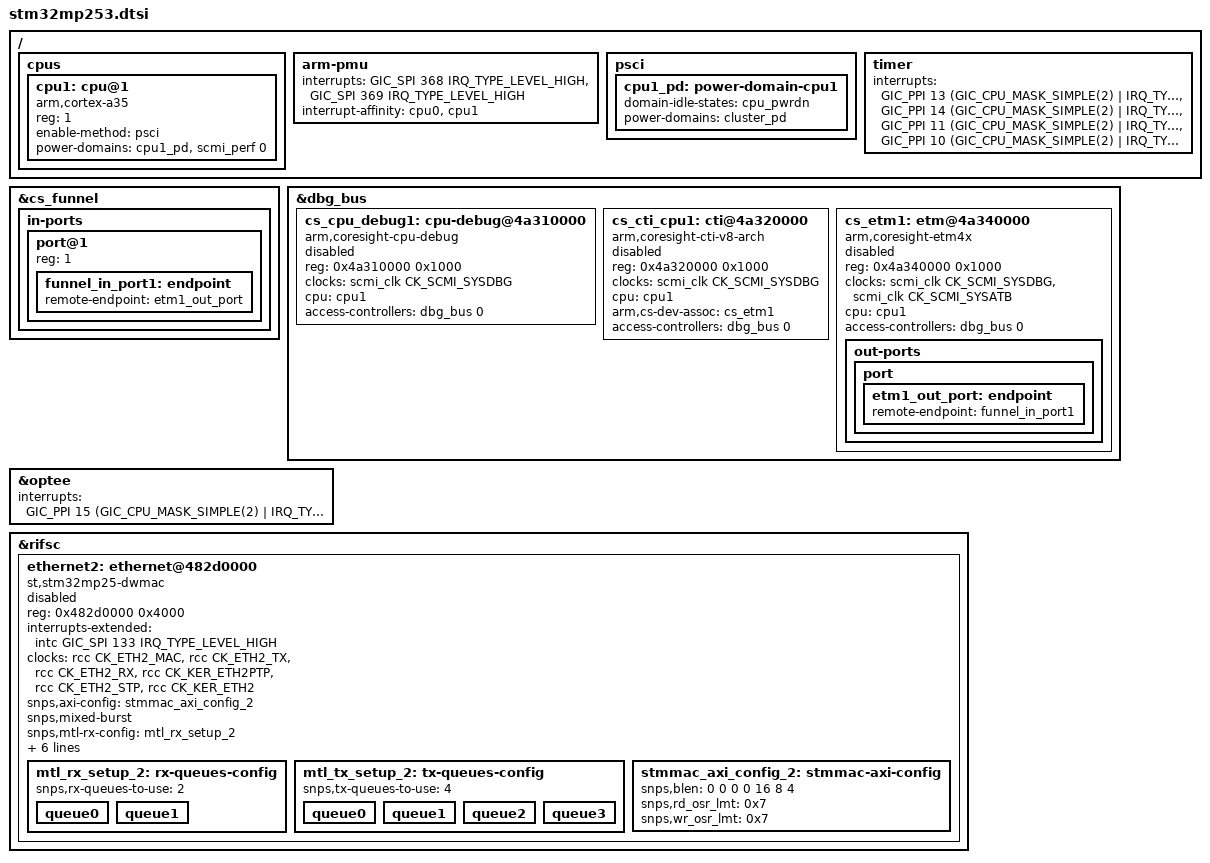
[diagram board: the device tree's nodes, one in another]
// SPDX-License-Identifier: (GPL-2.0-or-later OR BSD-3-Clause)
/*
 * Copyright (C) STMicroelectronics 2023 - All Rights Reserved
 * Author: Alexandre Torgue <alexandre.torgue@foss.st.com> for STMicroelectronics.
 */
#include "stm32mp251.dtsi"

/ {
	cpus {
		cpu1: cpu@1 {
			compatible = "arm,cortex-a35";
			device_type = "cpu";
			reg = <1>;
			enable-method = "psci";
			power-domains = <&cpu1_pd>, <&scmi_perf 0>;
			power-domain-names = "psci", "perf";
		};
	};

	arm-pmu {
		interrupts = <GIC_SPI 368 IRQ_TYPE_LEVEL_HIGH>,
			     <GIC_SPI 369 IRQ_TYPE_LEVEL_HIGH>;
		interrupt-affinity = <&cpu0>, <&cpu1>;
	};

	psci {
		cpu1_pd: power-domain-cpu1 {
			#power-domain-cells = <0>;
			domain-idle-states =  <&cpu_pwrdn>;
			power-domains = <&cluster_pd>;
		};
	};

	timer {
		interrupts = <GIC_PPI 13 (GIC_CPU_MASK_SIMPLE(2) | IRQ_TYPE_LEVEL_LOW)>,
			     <GIC_PPI 14 (GIC_CPU_MASK_SIMPLE(2) | IRQ_TYPE_LEVEL_LOW)>,
			     <GIC_PPI 11 (GIC_CPU_MASK_SIMPLE(2) | IRQ_TYPE_LEVEL_LOW)>,
			     <GIC_PPI 10 (GIC_CPU_MASK_SIMPLE(2) | IRQ_TYPE_LEVEL_LOW)>;
	};
};

&cs_funnel {
	in-ports {
		port@1 {
			reg = <1>;
			funnel_in_port1: endpoint {
				remote-endpoint = <&etm1_out_port>;
			};
		};
	};
};

&dbg_bus {
	cs_cpu_debug1: cpu-debug@4a310000 {
		compatible = "arm,coresight-cpu-debug", "arm,primecell";
		reg = <0x4a310000 0x1000>;
		clocks = <&scmi_clk CK_SCMI_SYSDBG>;
		clock-names = "apb_pclk";
		cpu = <&cpu1>;
		access-controllers = <&dbg_bus 0>;
		status = "disabled";
	};

	cs_cti_cpu1: cti@4a320000 {
		compatible = "arm,coresight-cti-v8-arch", "arm,coresight-cti", "arm,primecell";
		reg = <0x4a320000 0x1000>;
		clocks = <&scmi_clk CK_SCMI_SYSDBG>;
		clock-names = "apb_pclk";
		cpu = <&cpu1>;
		arm,cs-dev-assoc = <&cs_etm1>;
		access-controllers = <&dbg_bus 0>;
		status = "disabled";
	};

	cs_etm1: etm@4a340000 {
		compatible = "arm,coresight-etm4x", "arm,primecell";
		reg = <0x4a340000 0x1000>;
		clocks = <&scmi_clk CK_SCMI_SYSDBG>, <&scmi_clk CK_SCMI_SYSATB>;
		clock-names = "apb_pclk", "atclk";
		cpu = <&cpu1>;
		access-controllers = <&dbg_bus 0>;
		status = "disabled";

		out-ports {
			port {
				etm1_out_port: endpoint {
					remote-endpoint = <&funnel_in_port1>;
				};
			};
		};
	};
};

&optee {
	interrupts = <GIC_PPI 15 (GIC_CPU_MASK_SIMPLE(2) | IRQ_TYPE_LEVEL_LOW)>;
};

&rifsc {
	ethernet2: ethernet@482d0000 {
		compatible = "st,stm32mp25-dwmac", "snps,dwmac-5.20";
		reg = <0x482d0000 0x4000>;
		reg-names = "stmmaceth";
		interrupts-extended = <&intc GIC_SPI 133 IRQ_TYPE_LEVEL_HIGH>;
		interrupt-names = "macirq";
		clock-names = "stmmaceth",
			      "mac-clk-tx",
			      "mac-clk-rx",
			      "ptp_ref",
			      "ethstp",
			      "eth-ck";
		clocks = <&rcc CK_ETH2_MAC>,
			 <&rcc CK_ETH2_TX>,
			 <&rcc CK_ETH2_RX>,
			 <&rcc CK_KER_ETH2PTP>,
			 <&rcc CK_ETH2_STP>,
			 <&rcc CK_KER_ETH2>;
		snps,axi-config = <&stmmac_axi_config_2>;
		snps,mixed-burst;
		snps,mtl-rx-config = <&mtl_rx_setup_2>;
		snps,mtl-tx-config = <&mtl_tx_setup_2>;
		snps,pbl = <2>;
		snps,tso;
		st,syscon = <&syscfg 0x3400>;
		access-controllers = <&rifsc 61>;
		power-domains = <&d1_pd>;
		status = "disabled";

		mtl_rx_setup_2: rx-queues-config {
			snps,rx-queues-to-use = <2>;
			queue0 {};
			queue1 {};
		};

		mtl_tx_setup_2: tx-queues-config {
			snps,tx-queues-to-use = <4>;
			queue0 {};
			queue1 {};
			queue2 {};
			queue3 {};
		};

		stmmac_axi_config_2: stmmac-axi-config {
			snps,blen = <0 0 0 0 16 8 4>;
			snps,rd_osr_lmt = <0x7>;
			snps,wr_osr_lmt = <0x7>;
		};
	};
};
